# DMA_1.0 register map
Vendor: Texas Instruments
Peripheral module from a debugger description file (folder mspm0l211x_l112x).
Registers are 32-bit, read-write, no defined reset value unless marked. A register's access mark holds for its fields unless they carry their own. Offsets are as the file gives them; lines under a group give offsets from that group; [hi:lo] are bit positions; {n}, {i} and the like mark numbered series; 'fields as' and 'values as' point back to an identical list; <NAME> marks a mode.

## DMA
0x400 DMA_FSUB_0 — Subscriber Port 0
  [3:0] CHANID — 0 = disconnected. 1-255 = connected to channelID = CHANID.
0x404 DMA_FSUB_1 — Subscriber Port 1
  fields as DMA_FSUB_0
0x444 DMA_FPUB_1 — Publisher Port 0
  fields as DMA_FSUB_0
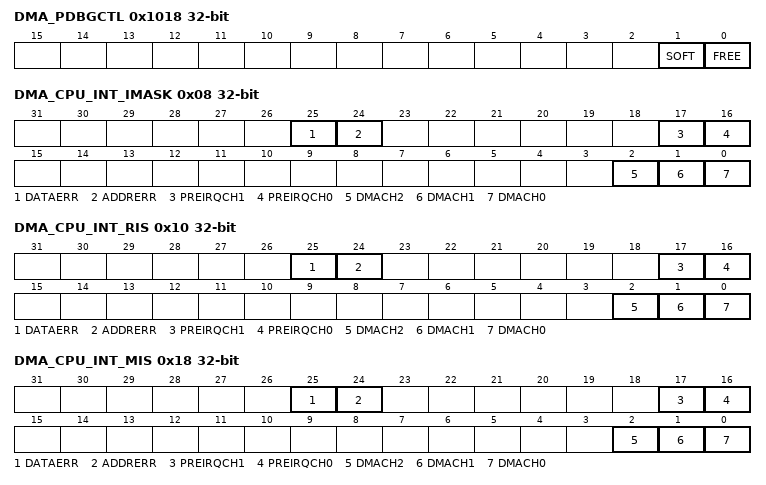
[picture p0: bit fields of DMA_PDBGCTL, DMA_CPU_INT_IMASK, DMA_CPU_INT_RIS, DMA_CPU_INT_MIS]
0x1018 DMA_PDBGCTL — Peripheral Debug Control
  [1] SOFT — Soft halt boundary control. This function is only available, if [FREE] is set to 'STOP'
    0=IMMEDIATE (The peripheral will halt immediately, even if the resultant state will result in corruption if the system is restarted); 1=DELAYED (The peripheral blocks the debug freeze until it has reached a boundary where it can resume without corruption)
  [0] FREE — Free run control
    0=STOP (The peripheral freezes functionality while the Core Halted input is asserted and resumes when it is deasserted.); 1=RUN (The peripheral ignores the state of the Core Halted input)
0x1020 DMA_CPU_INT group
  0x00 DMA_CPU_INT_IIDX ro — Interrupt index
    [7:0] STAT — Interrupt index status
      0=NO_INTR (No bit is set means there is no pending interrupt request); {v}=DMACH{v-1} (DMA Channel {v-1} size counter reached zero (DMASZ=0).) (v=1..16); {v}=PREIRQCH{v-17} (PRE-IRQ event for DMA Channel {v-17}.) (v=17..24); 25=ADDRERR (DMA address error, SRC address not reachable.); 26=DATAERR (DMA data error, SRC data might be corrupted (PAR or ECC error).)
  0x08 DMA_CPU_INT_IMASK — Interrupt mask
    [all] fields
      0=CLR (Clear interrupt mask bit); 1=SET (Set interrupt mask bit)
    [25] DATAERR — DMA data error, SRC data might be corrupted (PAR or ECC error).
    [24] ADDRERR — DMA address error, SRC address not reachable.
    [17] PREIRQCH1 — Pre-IRQ for Channel 1. Size counter reached Pre-IRQ threshold.
    [16] PREIRQCH0 — Pre-IRQ for Channel 0. Size counter reached Pre-IRQ threshold.
    [2] DMACH2 — DMA Channel 2 interrupt signal. Size counter reached zero (DMASZ=0).
    [1] DMACH1 — DMA Channel 1 interrupt signal. Size counter reached zero (DMASZ=0).
    [0] DMACH0 — DMA Channel 0 interrupt signal. Size counter reached zero (DMASZ=0).
  0x10 DMA_CPU_INT_RIS — Raw interrupt status
    [25] DATAERR — DMA data error, SRC data might be corrupted (PAR or ECC error).
      values as the fields of DMA_CPU_INT.DMA_CPU_INT_IMASK
    [24] ADDRERR — DMA address error, SRC address not reachable.
      values as the fields of DMA_CPU_INT.DMA_CPU_INT_IMASK
    [17] PREIRQCH1 — Pre-IRQ for Channel 1. Size counter reached Pre-IRQ threshold.
      values as the fields of DMA_CPU_INT.DMA_CPU_INT_IMASK
    [16] PREIRQCH0 — Pre-IRQ for Channel 0. Size counter reached Pre-IRQ threshold.
      values as the fields of DMA_CPU_INT.DMA_CPU_INT_IMASK
    [2] DMACH2 — DMA Channel 2 interrupt signals that size counter reached zero (DMASZ=0).
      0=CLR (Interrupt did not occur); 1=SET (Interrupt occurred)
    [1] DMACH1 — DMA Channel 1 interrupt signals that size counter reached zero (DMASZ=0).
      0=CLR (Interrupt did not occur); 1=SET (Interrupt occurred)
    [0] DMACH0 — DMA Channel 0 interrupt signals that size counter reached zero (DMASZ=0).
      0=CLR (Interrupt did not occur); 1=SET (Interrupt occurred)
  0x18 DMA_CPU_INT_MIS — Masked interrupt status
    [25] DATAERR — DMA data error, SRC data might be corrupted (PAR or ECC error).
      values as the fields of DMA_CPU_INT.DMA_CPU_INT_IMASK
    [24] ADDRERR — DMA address error, SRC address not reachable.
      values as the fields of DMA_CPU_INT.DMA_CPU_INT_IMASK
    [17] PREIRQCH1 — Pre-IRQ for Channel 1. Size counter reached Pre-IRQ threshold.
      values as the fields of DMA_CPU_INT.DMA_CPU_INT_IMASK
    [16] PREIRQCH0 — Pre-IRQ for Channel 0. Size counter reached Pre-IRQ threshold.
      values as the fields of DMA_CPU_INT.DMA_CPU_INT_IMASK
    [2] DMACH2 — DMA Channel 2 interrupt signals that size counter reached zero (DMASZ=0).
      0=CLR (Interrupt did not occur or is masked out); 1=SET (Interrupt occurred)
    [1] DMACH1 — DMA Channel 1 interrupt signals that size counter reached zero (DMASZ=0).
      values as DMACH2
    [0] DMACH0 — DMA Channel 0 interrupt signals that size counter reached zero (DMASZ=0).
      values as DMACH2
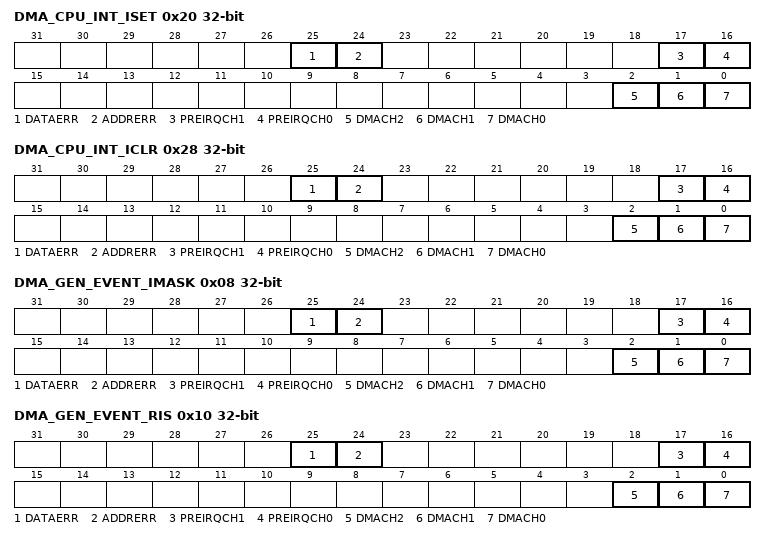
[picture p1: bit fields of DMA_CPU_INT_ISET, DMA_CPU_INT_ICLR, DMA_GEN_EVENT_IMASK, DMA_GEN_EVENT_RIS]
  0x20 DMA_CPU_INT_ISET — Interrupt set
    [25] DATAERR — DMA data error, SRC data might be corrupted (PAR or ECC error).
      values as the fields of DMA_CPU_INT.DMA_CPU_INT_IMASK
    [24] ADDRERR — DMA address error, SRC address not reachable.
      values as the fields of DMA_CPU_INT.DMA_CPU_INT_IMASK
    [17] PREIRQCH1 — Pre-IRQ for Channel 1. Size counter reached Pre-IRQ threshold.
      values as the fields of DMA_CPU_INT.DMA_CPU_INT_IMASK
    [16] PREIRQCH0 — Pre-IRQ for Channel 0. Size counter reached Pre-IRQ threshold.
      values as the fields of DMA_CPU_INT.DMA_CPU_INT_IMASK
    [2] DMACH2 — DMA Channel 2 interrupt signals that size counter reached zero (DMASZ=0).
      0=NO_EFFECT (Writing 0 has no effect); 1=SET (Set interrupt)
    [1] DMACH1 — DMA Channel 1 interrupt signals that size counter reached zero (DMASZ=0).
      0=NO_EFFECT (Writing 0 has no effect); 1=SET (Set interrupt)
    [0] DMACH0 — DMA Channel 0 interrupt signals that size counter reached zero (DMASZ=0).
      0=NO_EFFECT (Writing 0 has no effect); 1=SET (Set interrupt)
  0x28 DMA_CPU_INT_ICLR — Interrupt clear
    [25] DATAERR — DMA data error, SRC data might be corrupted (PAR or ECC error).
      values as the fields of DMA_CPU_INT.DMA_CPU_INT_IMASK
    [24] ADDRERR — DMA address error, SRC address not reachable.
      values as the fields of DMA_CPU_INT.DMA_CPU_INT_IMASK
    [17] PREIRQCH1 — Pre-IRQ for Channel 1. Size counter reached Pre-IRQ threshold.
      values as the fields of DMA_CPU_INT.DMA_CPU_INT_IMASK
    [16] PREIRQCH0 — Pre-IRQ for Channel 0. Size counter reached Pre-IRQ threshold.
      values as the fields of DMA_CPU_INT.DMA_CPU_INT_IMASK
    [2] DMACH2 — DMA Channel 2 interrupt signals that size counter reached zero (DMASZ=0).
      0=NO_EFFECT (Writing 0 has no effect); 1=CLR (Clear interrupt)
    [1] DMACH1 — DMA Channel 1 interrupt signals that size counter reached zero (DMASZ=0).
      values as DMACH2
    [0] DMACH0 — DMA Channel 0 interrupt signals that size counter reached zero (DMASZ=0).
      values as DMACH2
0x1050 DMA_GEN_EVENT group
  0x00 DMA_GEN_EVENT_IIDX ro — Interrupt index
    fields as DMA_CPU_INT.DMA_CPU_INT_IIDX
  0x08 DMA_GEN_EVENT_IMASK — Interrupt mask
    fields as DMA_CPU_INT.DMA_CPU_INT_IMASK
  0x10 DMA_GEN_EVENT_RIS — Raw interrupt status
    fields as DMA_CPU_INT.DMA_CPU_INT_RIS
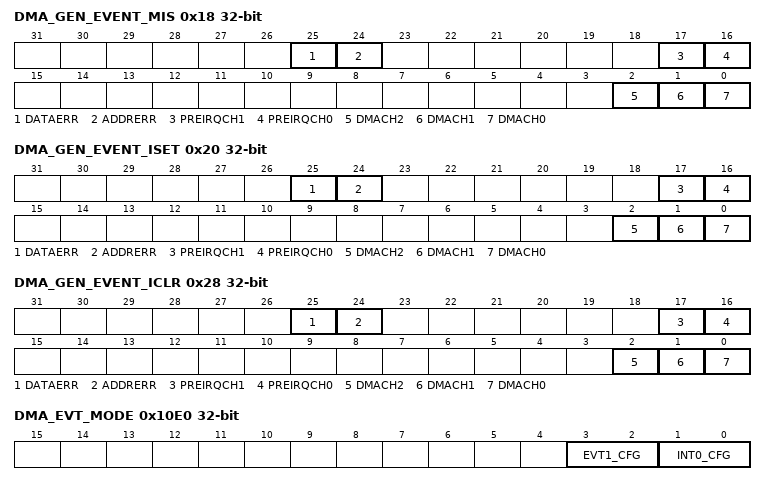
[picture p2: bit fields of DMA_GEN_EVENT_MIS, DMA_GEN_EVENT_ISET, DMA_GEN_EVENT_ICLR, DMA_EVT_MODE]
  0x18 DMA_GEN_EVENT_MIS — Masked interrupt status
    fields as DMA_CPU_INT.DMA_CPU_INT_MIS
  0x20 DMA_GEN_EVENT_ISET — Interrupt set
    fields as DMA_CPU_INT.DMA_CPU_INT_ISET
  0x28 DMA_GEN_EVENT_ICLR — Interrupt clear
    fields as DMA_CPU_INT.DMA_CPU_INT_ICLR
0x10E0 DMA_EVT_MODE ro — Event Mode
  [3:2] EVT1_CFG — Event line mode select for event corresponding to generic event GEN_EVENT
    0=DISABLE (The interrupt or event line is disabled.); 1=SOFTWARE (The interrupt or event line is in software mode. Software must clear the RIS.); 2=HARDWARE (The interrupt or event line is in hardware mode. The hardware (another module) clears automatically the associated RIS flag.)
  [1:0] INT0_CFG — Event line mode select for event corresponding to interrupt event CPU_INT
    values as EVT1_CFG
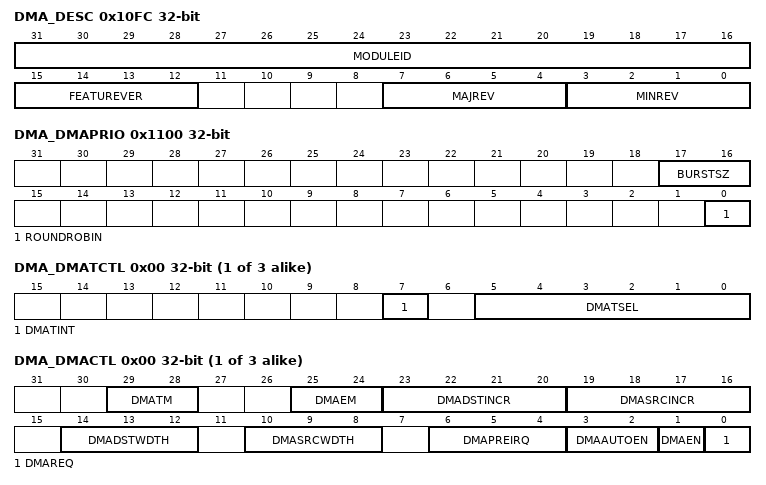
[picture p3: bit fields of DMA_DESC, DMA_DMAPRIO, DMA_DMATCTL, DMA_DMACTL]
0x10FC DMA_DESC — Module Description
  [31:16] MODULEID — Module identification contains a unique peripheral identification number. The assignments are maintained in a central database for all of the platform modules to ensure uniqueness.
    0=MINIMUM (Smallest value); 0xFFFF=MAXIMUM (Highest possible value)
  [15:12] FEATUREVER — Feature Set for the DMA: number of DMA channel minus one (e.g. 0->1ch, 2->3ch, 15->16ch).
    0=MINIMUM (Smallest value (1 channel)); 15=MAXIMUM (Highest value (16 channel))
  [7:4] MAJREV — Major rev of the IP
    0=MINIMUM (Smallest value); 15=MAXIMUM (Highest possible value)
  [3:0] MINREV — Minor rev of the IP
    values as MAJREV
0x1100 DMA_DMAPRIO — DMA Channel Priority Control
  [17:16] BURSTSZ — Define the burst size of a block transfer, before the priority is re-evaluated
    0=INFINITI (There is no burst size, the whole block transfer is completed on one transfer without interruption); 1=BURST_8 (The burst size is 8, after 9 transfers the block transfer is interrupted and the priority is reevaluated); 2=BUSRT_16 (The burst size is 16, after 17 transfers the block transfer is interrupted and the priority is reevaluated); 3=BURST_32 (The burst size is 32, after 33 transfers the block transfer is interrupted and the priority is reevaluated)
  [0] ROUNDROBIN — Round robin. This bit enables the round-robin DMA channel priorities.
    0=DISABLE (Roundrobin priority disabled, DMA channel priority is fixed: DMA0-DMA1-DMA2-...-DMA16); 1=ENABLE (Roundrobin priority enabled, DMA channel priority changes with each transfer)
{0x1110+4i} DMA_DMATRIG[{i}] (i=0..2) group
  0x00 DMA_DMATCTL — DMA Trigger Select
    [7] DMATINT — DMA Trigger by Internal Channel
      0=EXTERNAL (DMATSEL will define external trigger select as transfer trigger.); 1=INTERNAL (DMATSEL will define internal channel as transfer trigger select. 0-> Channel0-done, 1-> Channel1-done, ...)
    [5:0] DMATSEL — DMA Trigger Select Note: Reference the datasheet of the device to see the specific trigger mapping.
      0=MINIMUM (Smallest value); 0=DMAREQ (Software trigger request); 63=MAXIMUM (Highest possible value)
{0x1200+0x10*i} DMA_DMACHAN[{i}] (i=0..2) group
  0x00 DMA_DMACTL — DMA Channel Control
    [29:28] DMATM — DMA transfer mode register Note: The repeat-single (2h) and repeat-block (3h) transfer are only available in a FULL-channel configuration. Please consult the datasheet of the specific device to map which channel number has FULL or BASIC capability. In a BASIC channel configuration only the values for single (0h) and block (1h) transfer can be set.
      0=SINGLE (Single transfer. Each transfers requires a new trigger. When the DMASZ counts down to zero an event can be generated and the DMAEN is cleared.); 1=BLOCK (Block transfer. Each trigger transfers the complete block defined in DMASZ. After the transfer is complete an event can be generated and the DMAEN is cleared.); 2=RPTSNGL (Repeated single transfer. Each transfers requires a new trigger. When the DMASZ counts down to zero an event can be generated. After the last transfer the DMASA, DMADA, DAMSZ registers are restored to its initial value and the DMAEN stays enabled.); 3=RPTBLCK (Repeated block transfer. Each trigger transfers the complete block defined in DMASZ. After the last transfer the DMASA, DMADA, DAMSZ registers are restored to its initial value and the DMAEN stays enabled.)
    [25:24] DMAEM — DMA extended mode Note: The extended transfer modes are only available in a FULL-channel configuration. Please consult the datasheet of the specific device to map which channel number has FULL or BASIC capability. In a BASIC channel configuration this register is a read-only register and reads 0x0.
      0=NORMAL (Normal mode is related to transfers from SRC to DST); 1=GATHERMODE (Gather mode will read a data from an address table located at SA, and the data is transfered to the DA); 2=FILLMODE (Fill mode will copy the SA register content as data to DA); 3=TABLEMODE (Table mode will read an address and data value from SA and write the data to address)
    [23:20] DMADSTINCR — DMA destination increment. This bit selects automatic incrementing or decrementing of the destination address DMADA for each transfer. The amount of change to the DMADA is based on the definitin in the DMADSTWDTH. For example an increment of 1 (+1) on a WORD transfer will increment the DMADA by 4.
      0=UNCHANGED (Address is unchanged (+0)); 2=DECREMENT (Decremented by 1 (-1 * DMADSTWDTH)); 3=INCREMENT (Incremented by 1 (+1 * DMADSTWDTH)); {v}=STRIDE_{v-6} (Stride size {v-6} (+{v-6} * DMADSTWDTH)) (v=8..15)
    [19:16] DMASRCINCR — DMA source increment. This bit selects automatic incrementing or decrementing of the source address DMASA for each transfer. The amount of change to the DMASA is based on the definitin in the DMASRCWDTH. For example an increment of 1 (+1) on a WORD transfer will increment the DMASA by 4.
      0=UNCHANGED (Address is unchanged (+0)); 2=DECREMENT (Decremented by 1 (-1 * DMASRCWDTH)); 3=INCREMENT (Incremented by 1 (+1 * DMASRCWDTH)); {v}=STRIDE_{v-6} (Stride size {v-6} (+{v-6} * DMASRCWDTH)) (v=8..15)
    [14:12] DMADSTWDTH — DMA destination width. This bit selects the destination as a byte, half word, word, long word or long-long word.
      0=BYTE (Destination data width is BYTE (8-bit)); 1=HALF (Destination data width is HALF-WORD (16-bit)); 2=WORD (Destination data width is WORD (32-bit)); 3=LONG (Destination data width is LONG-WORD (64-bit)); 4=LONGLONG (Source data width is LONG-LONG-WORD (128-bit))
    [10:8] DMASRCWDTH — DMA source width. This bit selects the source data width as a byte, half word, word, long word or long-long word.
      0=BYTE (Source data width is BYTE (8-bit)); 1=HALF (Source data width is HALF-WORD (16-bit)); 2=WORD (Source data width is WORD (32-bit)); 3=LONG (Source data width is LONG-WORD (64-bit)); 4=LONGLONG (Source data width is LONG-LONG-WORD (128-bit))
    [6:4] DMAPREIRQ — Enable an early IRQ event. This can help software to react quicker to and DMA done event or allows some additional configuration before the channel is complete. Note: This register is only available in a FULL-channel configuration. Please consult the datasheet of the specific device to map which channel number has FULL or BASIC capability. In a BASIC configuration this register is a read only value and always reads as 0x0.
      0=PREIRQ_DISABLE (Pre-IRQ event disabled.); 1=PREIRQ_1 (Issure Pre-IRQ event when DMASZ=1); 2=PREIRQ_2 (Issure Pre-IRQ event when DMASZ=2); 3=PREIRQ_4 (Issure Pre-IRQ event when DMASZ=4); 4=PREIRQ_8 (Issure Pre-IRQ event when DMASZ=8); 5=PREIRQ_32 (Issure Pre-IRQ event when DMASZ=32); 6=PREIRQ_64 (Issure Pre-IRQ event when DMASZ=64); 7=PREIRQ_HALF (Issure Pre-IRQ event when DMASZ reached the half size point of the original transfer size)
    [3:2] DMAAUTOEN — Automatic DMA channel enable on DMASA, DMADA, DMASZ register write. If channel is configured as SW trigger (DMATCTL=0), the AUTOEN will set the DMAEN and DMAREQ. If channel is configured as HW trigger (DMACTL!=0), the AUTOEN will only set the DMAEN.
      0=DISABLE (No automatic DMA enable); 1=DMASA (Automatic DMA enable on DMASA register write.); 2=DMADA (Automatic DMA enable on DMADA register write.); 3=DMASZ (Automatic DMA enable on DMASZ register write.)
    [1] DMAEN — DMA enable
      0=DISABLE (DMA channel disabled); 1=ENABLE (DMA channel enabled)
    [0] DMAREQ — DMA request. Software-controlled DMA start. DMAREQ is reset automatically.
      0=IDLE (Default read value); 1=REQUEST (DMA transfer request (start DMA))
  0x04 DMA_DMASA — DMA Channel Source Address
    [31:0] ADDR
      0=MINIMUM (Smallest value); 0xFFFFFFFF=MAXIMUM (Highest possible value)
  0x08 DMA_DMADA — DMA Channel Destination Address
    fields as DMA_DMACHAN[0].DMA_DMASA
  0x0C DMA_DMASZ — DMA Channel Size
    [15:0] SIZE — DMA Channel Size in number of transfers
      values as DMA_DESC.MODULEID
